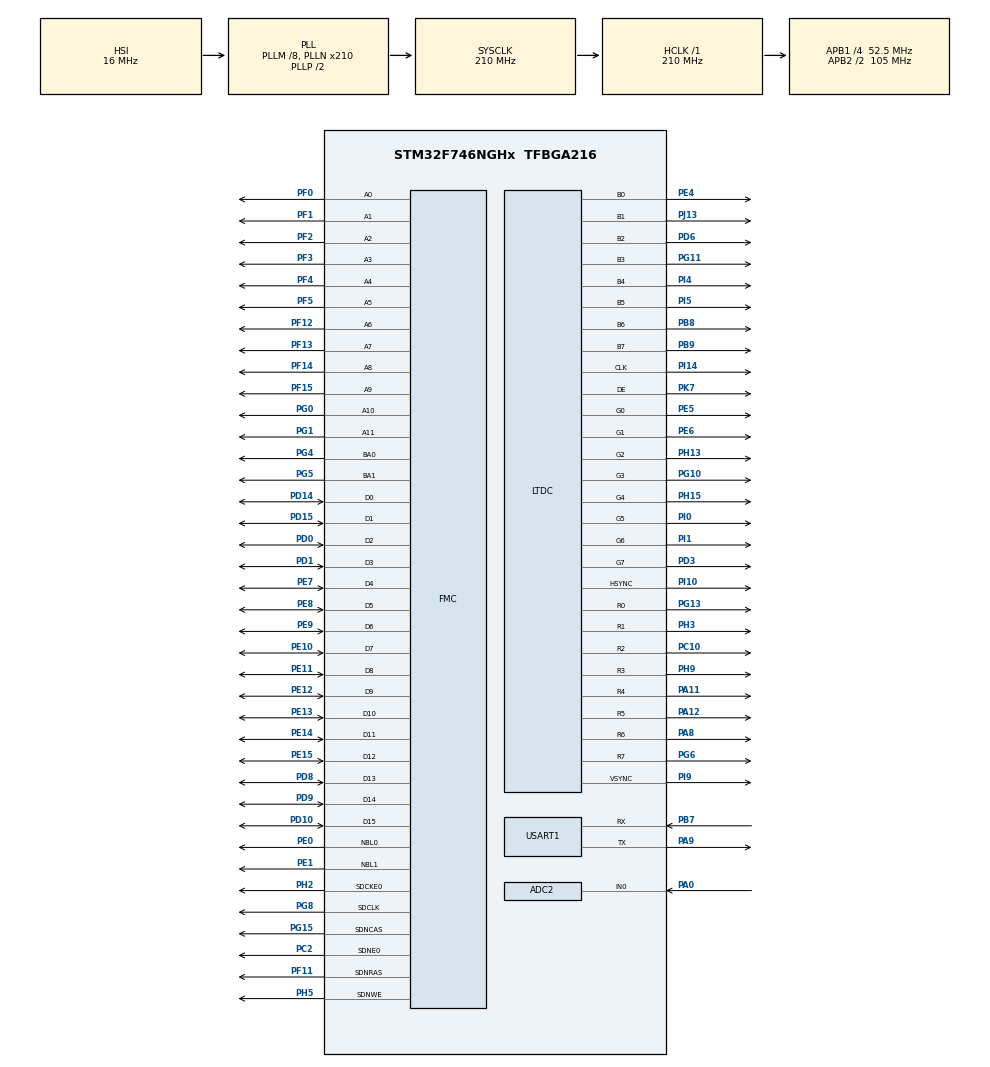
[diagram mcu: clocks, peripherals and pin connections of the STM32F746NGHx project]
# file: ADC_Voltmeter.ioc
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ADC2.Channel-0\#ChannelRegularConversion=ADC_CHANNEL_0
ADC2.ContinuousConvMode=ENABLE
ADC2.DMAContinuousRequests=ENABLE
ADC2.NbrOfConversionFlag=1
ADC2.Rank-0\#ChannelRegularConversion=1
ADC2.SamplingTime-0\#ChannelRegularConversion=ADC_SAMPLETIME_480CYCLES
Dma.ADC2.0.Direction=DMA_PERIPH_TO_MEMORY
Dma.ADC2.0.FIFOMode=DMA_FIFOMODE_DISABLE
Dma.ADC2.0.Instance=DMA2_Stream2
Dma.ADC2.0.MemDataAlignment=DMA_MDATAALIGN_HALFWORD
Dma.ADC2.0.MemInc=DMA_MINC_ENABLE
Dma.ADC2.0.Mode=DMA_CIRCULAR
Dma.ADC2.0.PeriphDataAlignment=DMA_PDATAALIGN_HALFWORD
Dma.ADC2.0.PeriphInc=DMA_PINC_DISABLE
Dma.ADC2.0.Priority=DMA_PRIORITY_LOW
Dma.Request0=ADC2
Mcu.Family=STM32F7
Mcu.Name=STM32F746NGHx
Mcu.Package=TFBGA216
NVIC.DMA2_Stream2_IRQn=true\:0\:0\:false\:false\:true\:false\:true\:true
NVIC.LTDC_IRQn=true\:0\:0\:false\:false\:true\:true\:true\:true
NVIC.PriorityGroup=NVIC_PRIORITYGROUP_4
PA0/WKUP.Signal=ADCx_IN0
PA11.Mode=RGB888
PA11.Signal=LTDC_R4
PA12.Mode=RGB888
PA12.Signal=LTDC_R5
PA13.Mode=Serial_Wire
PA13.Signal=SYS_JTMS-SWDIO
PA14.Mode=Serial_Wire
PA14.Signal=SYS_JTCK-SWCLK
PA8.Mode=RGB888
PA8.Signal=LTDC_R6
PA9.Mode=Asynchronous
PA9.Signal=USART1_TX
PB7.Mode=Asynchronous
PB7.Signal=USART1_RX
PB8.Mode=RGB888
PB8.Signal=LTDC_B6
PB9.Mode=RGB888
PB9.Signal=LTDC_B7
PC10.Mode=RGB888
PC10.Signal=LTDC_R2
PC14/OSC32_IN.Mode=LSE-External-Oscillator
PC14/OSC32_IN.Signal=RCC_OSC32_IN
PC15/OSC32_OUT.Mode=LSE-External-Oscillator
PC15/OSC32_OUT.Signal=RCC_OSC32_OUT
PC2.Mode=SdramChipSelect1_1
PC2.Signal=FMC_SDNE0
PD0.Signal=FMC_D2_DA2
PD1.Signal=FMC_D3_DA3
PD10.Signal=FMC_D15_DA15
PD14.Signal=FMC_D0_DA0
PD15.Signal=FMC_D1_DA1
PD3.Mode=RGB888
PD3.Signal=LTDC_G7
PD6.Mode=RGB888
PD6.Signal=LTDC_B2
PD8.Signal=FMC_D13_DA13
PD9.Signal=FMC_D14_DA14
PE0.Signal=FMC_NBL0
PE1.Signal=FMC_NBL1
PE10.Signal=FMC_D7_DA7
PE11.Signal=FMC_D8_DA8
PE12.Signal=FMC_D9_DA9
PE13.Signal=FMC_D10_DA10
PE14.Signal=FMC_D11_DA11
PE15.Signal=FMC_D12_DA12
PE4.Mode=RGB888
PE4.Signal=LTDC_B0
PE5.Mode=RGB888
PE5.Signal=LTDC_G0
PE6.Mode=RGB888
PE6.Signal=LTDC_G1
PE7.Signal=FMC_D4_DA4
PE8.Signal=FMC_D5_DA5
PE9.Signal=FMC_D6_DA6
PF0.Signal=FMC_A0
PF1.Signal=FMC_A1
PF11.Signal=FMC_SDNRAS
PF12.Signal=FMC_A6
PF13.Signal=FMC_A7
PF14.Signal=FMC_A8
PF15.Signal=FMC_A9
PF2.Signal=FMC_A2
PF3.Signal=FMC_A3
PF4.Signal=FMC_A4
PF5.Signal=FMC_A5
PG0.Signal=FMC_A10
PG1.Signal=FMC_A11
PG10.Mode=RGB888
PG10.Signal=LTDC_G3
PG11.Mode=RGB888
PG11.Signal=LTDC_B3
PG13.Mode=RGB888
PG13.Signal=LTDC_R0
PG15.Signal=FMC_SDNCAS
PG4.Signal=FMC_A14_BA0
PG5.Signal=FMC_A15_BA1
PG6.Mode=RGB888
PG6.Signal=LTDC_R7
PG8.Signal=FMC_SDCLK
PH0/OSC_IN.Mode=HSE-External-Oscillator
PH0/OSC_IN.Signal=RCC_OSC_IN
PH1/OSC_OUT.Mode=HSE-External-Oscillator
PH1/OSC_OUT.Signal=RCC_OSC_OUT
PH13.Mode=RGB888
PH13.Signal=LTDC_G2
PH15.Mode=RGB888
PH15.Signal=LTDC_G4
PH2.Mode=SdramChipSelect1_1
PH2.Signal=FMC_SDCKE0
PH3.Mode=RGB888
PH3.Signal=LTDC_R1
PH5.Signal=FMC_SDNWE
PH9.Mode=RGB888
PH9.Signal=LTDC_R3
PI0.Mode=RGB888
PI0.Signal=LTDC_G5
PI1.Mode=RGB888
PI1.Signal=LTDC_G6
PI10.Mode=RGB888
PI10.Signal=LTDC_HSYNC
PI14.Mode=RGB888
PI14.Signal=LTDC_CLK
PI4.Mode=RGB888
PI4.Signal=LTDC_B4
PI5.Mode=RGB888
PI5.Signal=LTDC_B5
PI9.Mode=RGB888
PI9.Signal=LTDC_VSYNC
PJ13.Mode=RGB888
PJ13.Signal=LTDC_B1
PK7.Mode=RGB888
PK7.Signal=LTDC_DE
ProjectManager.HeapSize=0x200
ProjectManager.StackSize=0x400
ProjectManager.TargetToolchain=CMake
RCC.AHBFreq_Value=210000000
RCC.APB1CLKDivider=RCC_HCLK_DIV4
RCC.APB1Freq_Value=52500000
RCC.APB1TimFreq_Value=105000000
RCC.APB2CLKDivider=RCC_HCLK_DIV2
RCC.APB2Freq_Value=105000000
RCC.APB2TimFreq_Value=210000000
RCC.CortexFreq_Value=210000000
RCC.HCLKFreq_Value=210000000
RCC.HSE_VALUE=25000000
RCC.HSI_VALUE=16000000
RCC.PLLM=8
RCC.PLLN=210
RCC.PLLSAIN=50
RCC.PLLSourceVirtual=RCC_PLLSOURCE_HSI
RCC.SYSCLKFreq_VALUE=210000000
RCC.SYSCLKSource=RCC_SYSCLKSOURCE_PLLCLK
RCC.USBFreq_Value=210000000
RCC.VCOOutputFreq_Value=420000000
SH.ADCx_IN0.0=ADC2_IN0,IN0
SH.FMC_A0.0=FMC_A0,12b-sda1
SH.FMC_A1.0=FMC_A1,12b-sda1
SH.FMC_A10.0=FMC_A10,12b-sda1
SH.FMC_A11.0=FMC_A11,12b-sda1
SH.FMC_A14_BA0.0=FMC_BA0,FourSdramBanks1
SH.FMC_A15_BA1.0=FMC_BA1,FourSdramBanks1
SH.FMC_A2.0=FMC_A2,12b-sda1
SH.FMC_A3.0=FMC_A3,12b-sda1
SH.FMC_A4.0=FMC_A4,12b-sda1
SH.FMC_A5.0=FMC_A5,12b-sda1
SH.FMC_A6.0=FMC_A6,12b-sda1
SH.FMC_A7.0=FMC_A7,12b-sda1
SH.FMC_A8.0=FMC_A8,12b-sda1
SH.FMC_A9.0=FMC_A9,12b-sda1
SH.FMC_D0_DA0.0=FMC_D0,sd-16b-d1
SH.FMC_D10_DA10.0=FMC_D10,sd-16b-d1
SH.FMC_D11_DA11.0=FMC_D11,sd-16b-d1
SH.FMC_D12_DA12.0=FMC_D12,sd-16b-d1
SH.FMC_D13_DA13.0=FMC_D13,sd-16b-d1
SH.FMC_D14_DA14.0=FMC_D14,sd-16b-d1
SH.FMC_D15_DA15.0=FMC_D15,sd-16b-d1
SH.FMC_D1_DA1.0=FMC_D1,sd-16b-d1
SH.FMC_D2_DA2.0=FMC_D2,sd-16b-d1
SH.FMC_D3_DA3.0=FMC_D3,sd-16b-d1
SH.FMC_D4_DA4.0=FMC_D4,sd-16b-d1
SH.FMC_D5_DA5.0=FMC_D5,sd-16b-d1
SH.FMC_D6_DA6.0=FMC_D6,sd-16b-d1
SH.FMC_D7_DA7.0=FMC_D7,sd-16b-d1
SH.FMC_D8_DA8.0=FMC_D8,sd-16b-d1
SH.FMC_D9_DA9.0=FMC_D9,sd-16b-d1
SH.FMC_NBL0.0=FMC_NBL0,Sd2ByteEnable1
SH.FMC_NBL1.0=FMC_NBL1,Sd2ByteEnable1
SH.FMC_SDCLK.0=FMC_SDCLK,12b-sda1
SH.FMC_SDNCAS.0=FMC_SDNCAS,12b-sda1
SH.FMC_SDNRAS.0=FMC_SDNRAS,12b-sda1
SH.FMC_SDNWE.0=FMC_SDNWE,12b-sda1
USART1.VirtualMode-Asynchronous=VM_ASYNC
VP_DMA2D_VS_DMA2D.Mode=DMA2D_Activate
board=STM32F746G-DISCO

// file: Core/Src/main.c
/* USER CODE BEGIN Header */
/**
  ******************************************************************************
  * @file           : main.c
  * @brief          : Main program body
  ******************************************************************************
  * @attention
  *
  * Copyright (c) 2024 STMicroelectronics.
  * All rights reserved.
  *
  * This software is licensed under terms that can be found in the LICENSE file
  * in the root directory of this software component.
  * If no LICENSE file comes with this software, it is provided AS-IS.
  *
  ******************************************************************************
  */
/* USER CODE END Header */
#include "main.h"
#include "adc.h"
#include "dma.h"
#include "dma2d.h"
#include "ltdc.h"
#include "usart.h"
#include "gpio.h"
#include "fmc.h"

/* USER CODE BEGIN Includes */
#include "stm32746g_discovery_lcd.h"
/* USER CODE END Includes */

/* USER CODE BEGIN PD */
#define PUTCHAR_PROTOTYPE int __io_putchar(int ch)
/* USER CODE END PD */

/* USER CODE BEGIN PV */
uint16_t adcValue = 0;
float voltage = 0;
/* USER CODE END PV */

void SystemClock_Config(void);

int main(void)
{

  /* MCU Configuration--------------------------------------------------------*/

  /* Reset of all peripherals, Initializes the Flash interface and the Systick. */
  HAL_Init();

  /* Configure the system clock */
  SystemClock_Config();

  /* Initialize all configured peripherals */
  MX_GPIO_Init();
  MX_DMA_Init();
  MX_ADC2_Init();
  MX_DMA2D_Init();
  MX_FMC_Init();
  MX_LTDC_Init();
  MX_USART1_UART_Init();
  /* USER CODE BEGIN 2 */
  // BSP LCD Initialization
  BSP_LCD_Init();
  BSP_LCD_LayerDefaultInit(0, LCD_FB_START_ADDRESS);
  BSP_LCD_DisplayOn();
  // Layer 0
  BSP_LCD_SelectLayer(0);
  BSP_LCD_Clear(LCD_COLOR_BLACK);
  BSP_LCD_SetBackColor(LCD_COLOR_TRANSPARENT);
  BSP_LCD_SetTextColor(LCD_COLOR_WHITE);
  // Title
  BSP_LCD_DisplayStringAt(0, 40, (uint8_t *)"Voltage Measurement", CENTER_MODE);
  // Start ADC
  HAL_ADC_Start_DMA(&hadc2, (uint32_t *)&adcValue, 1);
  /* USER CODE END 2 */

  /* Infinite loop */
  /* USER CODE BEGIN WHILE */
  char buff[20];
  while (1)
  {
    sprintf(buff, "ADC Reading: %4d", adcValue);
    BSP_LCD_DisplayStringAt(0, 100, buff, CENTER_MODE);
    voltage = ((float)adcValue) / 4096 * 3.3;
    sprintf(buff, "Voltage: %.3f V", voltage);
    BSP_LCD_DisplayStringAt(0, 140, buff, CENTER_MODE);
    HAL_Delay(200);
    /* USER CODE END WHILE */

  }
}

void SystemClock_Config(void)
{
  RCC_OscInitTypeDef RCC_OscInitStruct = {0};
  RCC_ClkInitTypeDef RCC_ClkInitStruct = {0};

  /** Configure LSE Drive Capability
  */
  HAL_PWR_EnableBkUpAccess();

  /** Configure the main internal regulator output voltage
  */
  __HAL_RCC_PWR_CLK_ENABLE();
  __HAL_PWR_VOLTAGESCALING_CONFIG(PWR_REGULATOR_VOLTAGE_SCALE1);

  /** Initializes the RCC Oscillators according to the specified parameters
  * in the RCC_OscInitTypeDef structure.
  */
  RCC_OscInitStruct.OscillatorType = RCC_OSCILLATORTYPE_HSI;
  RCC_OscInitStruct.HSIState = RCC_HSI_ON;
  RCC_OscInitStruct.HSICalibrationValue = RCC_HSICALIBRATION_DEFAULT;
  RCC_OscInitStruct.PLL.PLLState = RCC_PLL_ON;
  RCC_OscInitStruct.PLL.PLLSource = RCC_PLLSOURCE_HSI;
  RCC_OscInitStruct.PLL.PLLM = 8;
  RCC_OscInitStruct.PLL.PLLN = 210;
  RCC_OscInitStruct.PLL.PLLP = RCC_PLLP_DIV2;
  RCC_OscInitStruct.PLL.PLLQ = 2;
  if (HAL_RCC_OscConfig(&RCC_OscInitStruct) != HAL_OK)
  {
    Error_Handler();
  }

  /** Activate the Over-Drive mode
  */
  if (HAL_PWREx_EnableOverDrive() != HAL_OK)
  {
    Error_Handler();
  }

  /** Initializes the CPU, AHB and APB buses clocks
  */
  RCC_ClkInitStruct.ClockType = RCC_CLOCKTYPE_HCLK|RCC_CLOCKTYPE_SYSCLK
                              |RCC_CLOCKTYPE_PCLK1|RCC_CLOCKTYPE_PCLK2;
  RCC_ClkInitStruct.SYSCLKSource = RCC_SYSCLKSOURCE_PLLCLK;
  RCC_ClkInitStruct.AHBCLKDivider = RCC_SYSCLK_DIV1;
  RCC_ClkInitStruct.APB1CLKDivider = RCC_HCLK_DIV4;
  RCC_ClkInitStruct.APB2CLKDivider = RCC_HCLK_DIV2;

  if (HAL_RCC_ClockConfig(&RCC_ClkInitStruct, FLASH_LATENCY_6) != HAL_OK)
  {
    Error_Handler();
  }
}

/* USER CODE BEGIN 4 */
PUTCHAR_PROTOTYPE
{
  HAL_UART_Transmit(&huart1, (uint8_t *)&ch, 1, 0xFFFF);
  return ch;
}
/* USER CODE END 4 */

void Error_Handler(void)
{
  __disable_irq();
  while (1)
  {
  }
}
